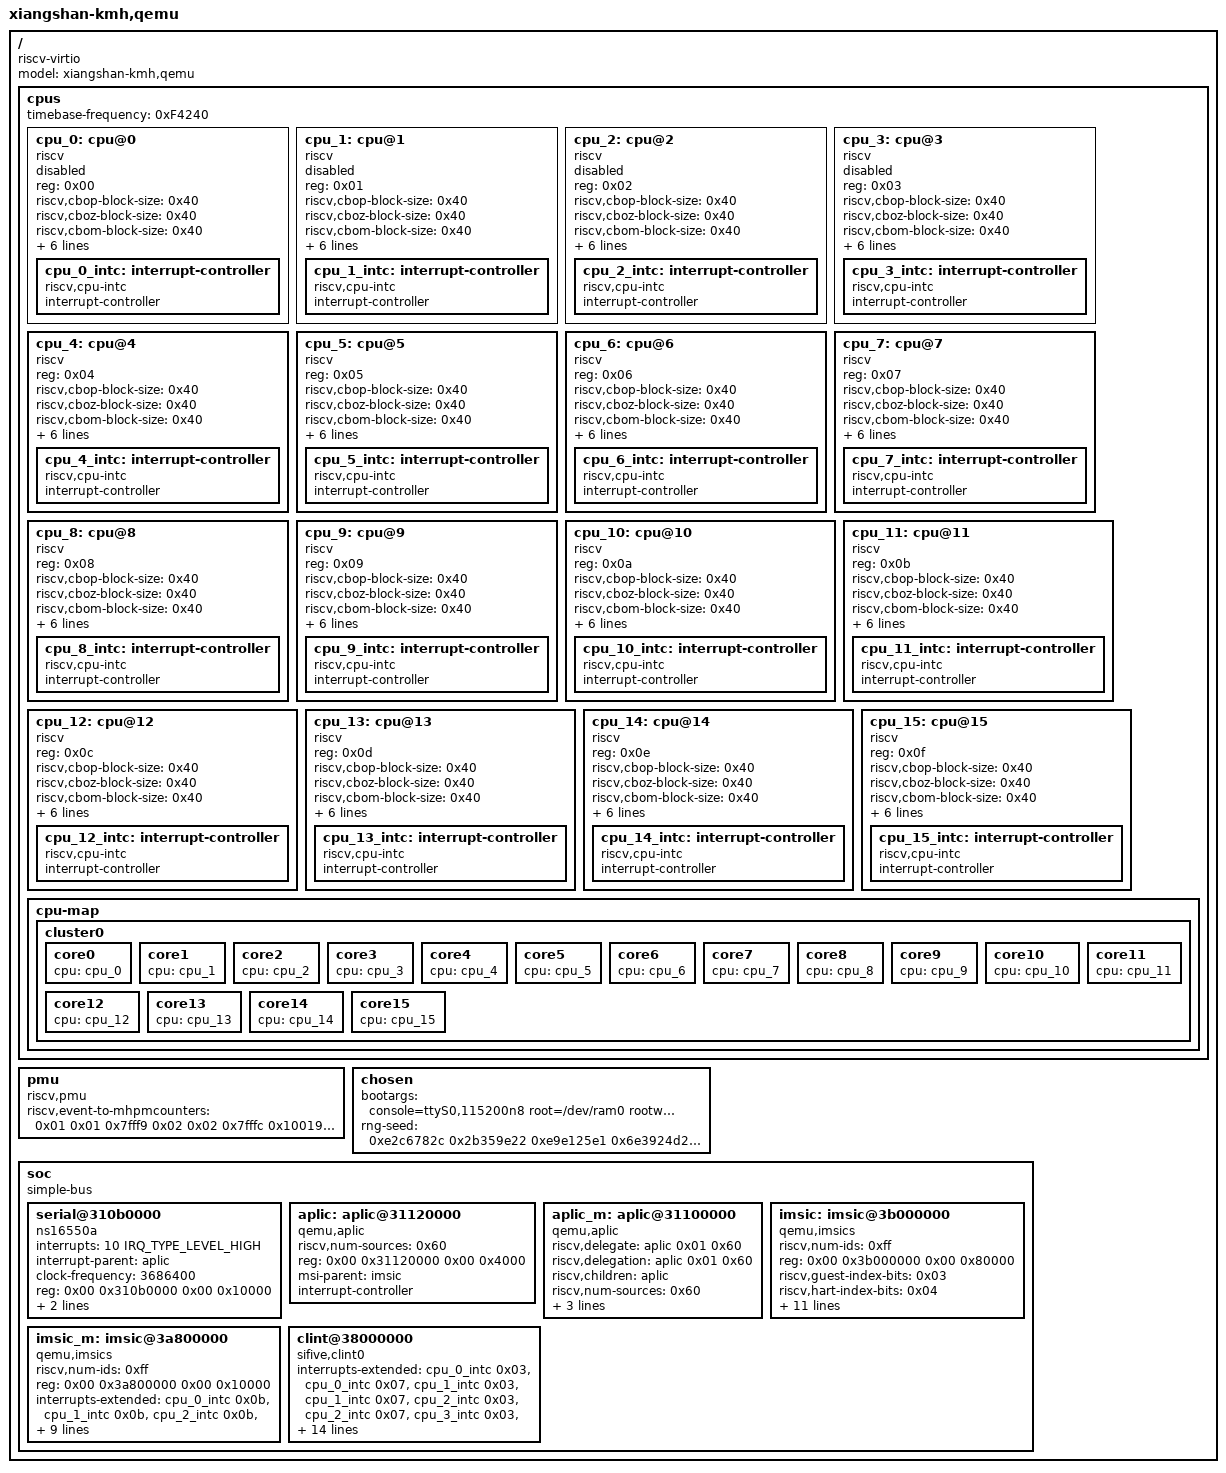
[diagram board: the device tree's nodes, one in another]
/*
 * SPDX-License-Identifier: Apache-2.0
 * Copyright (c) 2025 KapaXL (kapa.xl@outlook.com)
 *
 * QEMU RISCV xiangshan-kunminghu machine
 */

/dts-v1/;

#define IRQ_TYPE_LEVEL_HIGH	4

#include "memory.dtsi"

/ {
	#address-cells = <0x02>;
	#size-cells = <0x02>;
	compatible = "riscv-virtio";
	model = "xiangshan-kmh,qemu";

	cpus {
		#address-cells = <0x01>;
		#size-cells = <0x00>;
		timebase-frequency = <0xF4240>;

		cpu_0: cpu@0 {
			device_type = "cpu";
			reg = <0x00>;
			status = "disabled";
			compatible = "riscv";
			riscv,cbop-block-size = <0x40>;
			riscv,cboz-block-size = <0x40>;
			riscv,cbom-block-size = <0x40>;
			riscv,isa-extensions = "i\0m\0a\0f\0d\0c\0h\0zic64b\0zicbom\0zicbop\0zicboz\0ziccamoa\0ziccif\0zicclsm\0ziccrse\0zicntr\0zicsr\0zifencei\0zihintntl\0zihintpause\0zihpm\0zmmul\0za64rs\0zaamo\0zalrsc\0zawrs\0zfa\0zca\0zcd\0zba\0zbb\0zbc\0zbs\0sdtrig\0shcounterenw\0shgatpa\0shtvala\0shvsatpa\0shvstvala\0shvstvecd\0smaia\0ssaia\0ssccptr\0sscounterenw\0ssstrict\0sstc\0sstvala\0sstvecd\0ssu64xl\0svadu\0svvptc";
			riscv,isa-base = "rv64i";
			riscv,isa = "rv64imafdch_zic64b_zicbom_zicbop_zicboz_ziccamoa_ziccif_zicclsm_ziccrse_zicntr_zicsr_zifencei_zihintntl_zihintpause_zihpm_zmmul_za64rs_zaamo_zalrsc_zawrs_zfa_zca_zcd_zba_zbb_zbc_zbs_sdtrig_shcounterenw_shgatpa_shtvala_shvsatpa_shvstvala_shvstvecd_smaia_ssaia_ssccptr_sscounterenw_ssstrict_sstc_sstvala_sstvecd_ssu64xl_svadu_svvptc";
			mmu-type = "riscv,sv57";

			cpu_0_intc: interrupt-controller {
				#interrupt-cells = <0x01>;
				interrupt-controller;
				compatible = "riscv,cpu-intc";
			};
		};

		cpu_1: cpu@1 {
			device_type = "cpu";
			reg = <0x01>;
			status = "disabled";
			compatible = "riscv";
			riscv,cbop-block-size = <0x40>;
			riscv,cboz-block-size = <0x40>;
			riscv,cbom-block-size = <0x40>;
			riscv,isa-extensions = "i\0m\0a\0f\0d\0c\0h\0zic64b\0zicbom\0zicbop\0zicboz\0ziccamoa\0ziccif\0zicclsm\0ziccrse\0zicntr\0zicsr\0zifencei\0zihintntl\0zihintpause\0zihpm\0zmmul\0za64rs\0zaamo\0zalrsc\0zawrs\0zfa\0zca\0zcd\0zba\0zbb\0zbc\0zbs\0sdtrig\0shcounterenw\0shgatpa\0shtvala\0shvsatpa\0shvstvala\0shvstvecd\0smaia\0ssaia\0ssccptr\0sscounterenw\0ssstrict\0sstc\0sstvala\0sstvecd\0ssu64xl\0svadu\0svvptc";
			riscv,isa-base = "rv64i";
			riscv,isa = "rv64imafdch_zic64b_zicbom_zicbop_zicboz_ziccamoa_ziccif_zicclsm_ziccrse_zicntr_zicsr_zifencei_zihintntl_zihintpause_zihpm_zmmul_za64rs_zaamo_zalrsc_zawrs_zfa_zca_zcd_zba_zbb_zbc_zbs_sdtrig_shcounterenw_shgatpa_shtvala_shvsatpa_shvstvala_shvstvecd_smaia_ssaia_ssccptr_sscounterenw_ssstrict_sstc_sstvala_sstvecd_ssu64xl_svadu_svvptc";
			mmu-type = "riscv,sv57";

			cpu_1_intc: interrupt-controller {
				#interrupt-cells = <0x01>;
				interrupt-controller;
				compatible = "riscv,cpu-intc";
			};
		};
		cpu_2: cpu@2 {
			device_type = "cpu";
			reg = <0x02>;
			status = "disabled";
			compatible = "riscv";
			riscv,cbop-block-size = <0x40>;
			riscv,cboz-block-size = <0x40>;
			riscv,cbom-block-size = <0x40>;
			riscv,isa-extensions = "i\0m\0a\0f\0d\0c\0h\0zic64b\0zicbom\0zicbop\0zicboz\0ziccamoa\0ziccif\0zicclsm\0ziccrse\0zicntr\0zicsr\0zifencei\0zihintntl\0zihintpause\0zihpm\0zmmul\0za64rs\0zaamo\0zalrsc\0zawrs\0zfa\0zca\0zcd\0zba\0zbb\0zbc\0zbs\0sdtrig\0shcounterenw\0shgatpa\0shtvala\0shvsatpa\0shvstvala\0shvstvecd\0smaia\0ssaia\0ssccptr\0sscounterenw\0ssstrict\0sstc\0sstvala\0sstvecd\0ssu64xl\0svadu\0svvptc";
			riscv,isa-base = "rv64i";
			riscv,isa = "rv64imafdch_zic64b_zicbom_zicbop_zicboz_ziccamoa_ziccif_zicclsm_ziccrse_zicntr_zicsr_zifencei_zihintntl_zihintpause_zihpm_zmmul_za64rs_zaamo_zalrsc_zawrs_zfa_zca_zcd_zba_zbb_zbc_zbs_sdtrig_shcounterenw_shgatpa_shtvala_shvsatpa_shvstvala_shvstvecd_smaia_ssaia_ssccptr_sscounterenw_ssstrict_sstc_sstvala_sstvecd_ssu64xl_svadu_svvptc";
			mmu-type = "riscv,sv57";

			cpu_2_intc: interrupt-controller {
				#interrupt-cells = <0x01>;
				interrupt-controller;
				compatible = "riscv,cpu-intc";
			};
		};
		cpu_3: cpu@3 {
			device_type = "cpu";
			reg = <0x03>;
			status = "disabled";
			compatible = "riscv";
			riscv,cbop-block-size = <0x40>;
			riscv,cboz-block-size = <0x40>;
			riscv,cbom-block-size = <0x40>;
			riscv,isa-extensions = "i\0m\0a\0f\0d\0c\0h\0zic64b\0zicbom\0zicbop\0zicboz\0ziccamoa\0ziccif\0zicclsm\0ziccrse\0zicntr\0zicsr\0zifencei\0zihintntl\0zihintpause\0zihpm\0zmmul\0za64rs\0zaamo\0zalrsc\0zawrs\0zfa\0zca\0zcd\0zba\0zbb\0zbc\0zbs\0sdtrig\0shcounterenw\0shgatpa\0shtvala\0shvsatpa\0shvstvala\0shvstvecd\0smaia\0ssaia\0ssccptr\0sscounterenw\0ssstrict\0sstc\0sstvala\0sstvecd\0ssu64xl\0svadu\0svvptc";
			riscv,isa-base = "rv64i";
			riscv,isa = "rv64imafdch_zic64b_zicbom_zicbop_zicboz_ziccamoa_ziccif_zicclsm_ziccrse_zicntr_zicsr_zifencei_zihintntl_zihintpause_zihpm_zmmul_za64rs_zaamo_zalrsc_zawrs_zfa_zca_zcd_zba_zbb_zbc_zbs_sdtrig_shcounterenw_shgatpa_shtvala_shvsatpa_shvstvala_shvstvecd_smaia_ssaia_ssccptr_sscounterenw_ssstrict_sstc_sstvala_sstvecd_ssu64xl_svadu_svvptc";
			mmu-type = "riscv,sv57";

			cpu_3_intc: interrupt-controller {
				#interrupt-cells = <0x01>;
				interrupt-controller;
				compatible = "riscv,cpu-intc";
			};
		};
		cpu_4: cpu@4 {
			device_type = "cpu";
			reg = <0x04>;
			status = "okay";
			compatible = "riscv";
			riscv,cbop-block-size = <0x40>;
			riscv,cboz-block-size = <0x40>;
			riscv,cbom-block-size = <0x40>;
			riscv,isa-extensions = "i\0m\0a\0f\0d\0c\0h\0zic64b\0zicbom\0zicbop\0zicboz\0ziccamoa\0ziccif\0zicclsm\0ziccrse\0zicntr\0zicsr\0zifencei\0zihintntl\0zihintpause\0zihpm\0zmmul\0za64rs\0zaamo\0zalrsc\0zawrs\0zfa\0zca\0zcd\0zba\0zbb\0zbc\0zbs\0sdtrig\0shcounterenw\0shgatpa\0shtvala\0shvsatpa\0shvstvala\0shvstvecd\0smaia\0ssaia\0ssccptr\0sscounterenw\0ssstrict\0sstc\0sstvala\0sstvecd\0ssu64xl\0svadu\0svvptc";
			riscv,isa-base = "rv64i";
			riscv,isa = "rv64imafdch_zic64b_zicbom_zicbop_zicboz_ziccamoa_ziccif_zicclsm_ziccrse_zicntr_zicsr_zifencei_zihintntl_zihintpause_zihpm_zmmul_za64rs_zaamo_zalrsc_zawrs_zfa_zca_zcd_zba_zbb_zbc_zbs_sdtrig_shcounterenw_shgatpa_shtvala_shvsatpa_shvstvala_shvstvecd_smaia_ssaia_ssccptr_sscounterenw_ssstrict_sstc_sstvala_sstvecd_ssu64xl_svadu_svvptc";
			mmu-type = "riscv,sv57";

			cpu_4_intc: interrupt-controller {
				#interrupt-cells = <0x01>;
				interrupt-controller;
				compatible = "riscv,cpu-intc";
			};
		};
		cpu_5: cpu@5 {
			device_type = "cpu";
			reg = <0x05>;
			status = "okay";
			compatible = "riscv";
			riscv,cbop-block-size = <0x40>;
			riscv,cboz-block-size = <0x40>;
			riscv,cbom-block-size = <0x40>;
			riscv,isa-extensions = "i\0m\0a\0f\0d\0c\0h\0zic64b\0zicbom\0zicbop\0zicboz\0ziccamoa\0ziccif\0zicclsm\0ziccrse\0zicntr\0zicsr\0zifencei\0zihintntl\0zihintpause\0zihpm\0zmmul\0za64rs\0zaamo\0zalrsc\0zawrs\0zfa\0zca\0zcd\0zba\0zbb\0zbc\0zbs\0sdtrig\0shcounterenw\0shgatpa\0shtvala\0shvsatpa\0shvstvala\0shvstvecd\0smaia\0ssaia\0ssccptr\0sscounterenw\0ssstrict\0sstc\0sstvala\0sstvecd\0ssu64xl\0svadu\0svvptc";
			riscv,isa-base = "rv64i";
			riscv,isa = "rv64imafdch_zic64b_zicbom_zicbop_zicboz_ziccamoa_ziccif_zicclsm_ziccrse_zicntr_zicsr_zifencei_zihintntl_zihintpause_zihpm_zmmul_za64rs_zaamo_zalrsc_zawrs_zfa_zca_zcd_zba_zbb_zbc_zbs_sdtrig_shcounterenw_shgatpa_shtvala_shvsatpa_shvstvala_shvstvecd_smaia_ssaia_ssccptr_sscounterenw_ssstrict_sstc_sstvala_sstvecd_ssu64xl_svadu_svvptc";
			mmu-type = "riscv,sv57";

			cpu_5_intc: interrupt-controller {
				#interrupt-cells = <0x01>;
				interrupt-controller;
				compatible = "riscv,cpu-intc";
			};
		};
		cpu_6: cpu@6 {
			device_type = "cpu";
			reg = <0x06>;
			status = "okay";
			compatible = "riscv";
			riscv,cbop-block-size = <0x40>;
			riscv,cboz-block-size = <0x40>;
			riscv,cbom-block-size = <0x40>;
			riscv,isa-extensions = "i\0m\0a\0f\0d\0c\0h\0zic64b\0zicbom\0zicbop\0zicboz\0ziccamoa\0ziccif\0zicclsm\0ziccrse\0zicntr\0zicsr\0zifencei\0zihintntl\0zihintpause\0zihpm\0zmmul\0za64rs\0zaamo\0zalrsc\0zawrs\0zfa\0zca\0zcd\0zba\0zbb\0zbc\0zbs\0sdtrig\0shcounterenw\0shgatpa\0shtvala\0shvsatpa\0shvstvala\0shvstvecd\0smaia\0ssaia\0ssccptr\0sscounterenw\0ssstrict\0sstc\0sstvala\0sstvecd\0ssu64xl\0svadu\0svvptc";
			riscv,isa-base = "rv64i";
			riscv,isa = "rv64imafdch_zic64b_zicbom_zicbop_zicboz_ziccamoa_ziccif_zicclsm_ziccrse_zicntr_zicsr_zifencei_zihintntl_zihintpause_zihpm_zmmul_za64rs_zaamo_zalrsc_zawrs_zfa_zca_zcd_zba_zbb_zbc_zbs_sdtrig_shcounterenw_shgatpa_shtvala_shvsatpa_shvstvala_shvstvecd_smaia_ssaia_ssccptr_sscounterenw_ssstrict_sstc_sstvala_sstvecd_ssu64xl_svadu_svvptc";
			mmu-type = "riscv,sv57";

			cpu_6_intc: interrupt-controller {
				#interrupt-cells = <0x01>;
				interrupt-controller;
				compatible = "riscv,cpu-intc";
			};
		};
		cpu_7: cpu@7 {
			device_type = "cpu";
			reg = <0x07>;
			status = "okay";
			compatible = "riscv";
			riscv,cbop-block-size = <0x40>;
			riscv,cboz-block-size = <0x40>;
			riscv,cbom-block-size = <0x40>;
			riscv,isa-extensions = "i\0m\0a\0f\0d\0c\0h\0zic64b\0zicbom\0zicbop\0zicboz\0ziccamoa\0ziccif\0zicclsm\0ziccrse\0zicntr\0zicsr\0zifencei\0zihintntl\0zihintpause\0zihpm\0zmmul\0za64rs\0zaamo\0zalrsc\0zawrs\0zfa\0zca\0zcd\0zba\0zbb\0zbc\0zbs\0sdtrig\0shcounterenw\0shgatpa\0shtvala\0shvsatpa\0shvstvala\0shvstvecd\0smaia\0ssaia\0ssccptr\0sscounterenw\0ssstrict\0sstc\0sstvala\0sstvecd\0ssu64xl\0svadu\0svvptc";
			riscv,isa-base = "rv64i";
			riscv,isa = "rv64imafdch_zic64b_zicbom_zicbop_zicboz_ziccamoa_ziccif_zicclsm_ziccrse_zicntr_zicsr_zifencei_zihintntl_zihintpause_zihpm_zmmul_za64rs_zaamo_zalrsc_zawrs_zfa_zca_zcd_zba_zbb_zbc_zbs_sdtrig_shcounterenw_shgatpa_shtvala_shvsatpa_shvstvala_shvstvecd_smaia_ssaia_ssccptr_sscounterenw_ssstrict_sstc_sstvala_sstvecd_ssu64xl_svadu_svvptc";
			mmu-type = "riscv,sv57";

			cpu_7_intc: interrupt-controller {
				#interrupt-cells = <0x01>;
				interrupt-controller;
				compatible = "riscv,cpu-intc";
			};
		};
		cpu_8: cpu@8 {
			device_type = "cpu";
			reg = <0x08>;
			status = "okay";
			compatible = "riscv";
			riscv,cbop-block-size = <0x40>;
			riscv,cboz-block-size = <0x40>;
			riscv,cbom-block-size = <0x40>;
			riscv,isa-extensions = "i\0m\0a\0f\0d\0c\0h\0zic64b\0zicbom\0zicbop\0zicboz\0ziccamoa\0ziccif\0zicclsm\0ziccrse\0zicntr\0zicsr\0zifencei\0zihintntl\0zihintpause\0zihpm\0zmmul\0za64rs\0zaamo\0zalrsc\0zawrs\0zfa\0zca\0zcd\0zba\0zbb\0zbc\0zbs\0sdtrig\0shcounterenw\0shgatpa\0shtvala\0shvsatpa\0shvstvala\0shvstvecd\0smaia\0ssaia\0ssccptr\0sscounterenw\0ssstrict\0sstc\0sstvala\0sstvecd\0ssu64xl\0svadu\0svvptc";
			riscv,isa-base = "rv64i";
			riscv,isa = "rv64imafdch_zic64b_zicbom_zicbop_zicboz_ziccamoa_ziccif_zicclsm_ziccrse_zicntr_zicsr_zifencei_zihintntl_zihintpause_zihpm_zmmul_za64rs_zaamo_zalrsc_zawrs_zfa_zca_zcd_zba_zbb_zbc_zbs_sdtrig_shcounterenw_shgatpa_shtvala_shvsatpa_shvstvala_shvstvecd_smaia_ssaia_ssccptr_sscounterenw_ssstrict_sstc_sstvala_sstvecd_ssu64xl_svadu_svvptc";
			mmu-type = "riscv,sv57";

			cpu_8_intc: interrupt-controller {
				#interrupt-cells = <0x01>;
				interrupt-controller;
				compatible = "riscv,cpu-intc";
			};
		};
		cpu_9: cpu@9 {
			device_type = "cpu";
			reg = <0x09>;
			status = "okay";
			compatible = "riscv";
			riscv,cbop-block-size = <0x40>;
			riscv,cboz-block-size = <0x40>;
			riscv,cbom-block-size = <0x40>;
			riscv,isa-extensions = "i\0m\0a\0f\0d\0c\0h\0zic64b\0zicbom\0zicbop\0zicboz\0ziccamoa\0ziccif\0zicclsm\0ziccrse\0zicntr\0zicsr\0zifencei\0zihintntl\0zihintpause\0zihpm\0zmmul\0za64rs\0zaamo\0zalrsc\0zawrs\0zfa\0zca\0zcd\0zba\0zbb\0zbc\0zbs\0sdtrig\0shcounterenw\0shgatpa\0shtvala\0shvsatpa\0shvstvala\0shvstvecd\0smaia\0ssaia\0ssccptr\0sscounterenw\0ssstrict\0sstc\0sstvala\0sstvecd\0ssu64xl\0svadu\0svvptc";
			riscv,isa-base = "rv64i";
			riscv,isa = "rv64imafdch_zic64b_zicbom_zicbop_zicboz_ziccamoa_ziccif_zicclsm_ziccrse_zicntr_zicsr_zifencei_zihintntl_zihintpause_zihpm_zmmul_za64rs_zaamo_zalrsc_zawrs_zfa_zca_zcd_zba_zbb_zbc_zbs_sdtrig_shcounterenw_shgatpa_shtvala_shvsatpa_shvstvala_shvstvecd_smaia_ssaia_ssccptr_sscounterenw_ssstrict_sstc_sstvala_sstvecd_ssu64xl_svadu_svvptc";
			mmu-type = "riscv,sv57";

			cpu_9_intc: interrupt-controller {
				#interrupt-cells = <0x01>;
				interrupt-controller;
				compatible = "riscv,cpu-intc";
			};
		};
		cpu_10: cpu@10 {
			device_type = "cpu";
			reg = <0x0a>;
			status = "okay";
			compatible = "riscv";
			riscv,cbop-block-size = <0x40>;
			riscv,cboz-block-size = <0x40>;
			riscv,cbom-block-size = <0x40>;
			riscv,isa-extensions = "i\0m\0a\0f\0d\0c\0h\0zic64b\0zicbom\0zicbop\0zicboz\0ziccamoa\0ziccif\0zicclsm\0ziccrse\0zicntr\0zicsr\0zifencei\0zihintntl\0zihintpause\0zihpm\0zmmul\0za64rs\0zaamo\0zalrsc\0zawrs\0zfa\0zca\0zcd\0zba\0zbb\0zbc\0zbs\0sdtrig\0shcounterenw\0shgatpa\0shtvala\0shvsatpa\0shvstvala\0shvstvecd\0smaia\0ssaia\0ssccptr\0sscounterenw\0ssstrict\0sstc\0sstvala\0sstvecd\0ssu64xl\0svadu\0svvptc";
			riscv,isa-base = "rv64i";
			riscv,isa = "rv64imafdch_zic64b_zicbom_zicbop_zicboz_ziccamoa_ziccif_zicclsm_ziccrse_zicntr_zicsr_zifencei_zihintntl_zihintpause_zihpm_zmmul_za64rs_zaamo_zalrsc_zawrs_zfa_zca_zcd_zba_zbb_zbc_zbs_sdtrig_shcounterenw_shgatpa_shtvala_shvsatpa_shvstvala_shvstvecd_smaia_ssaia_ssccptr_sscounterenw_ssstrict_sstc_sstvala_sstvecd_ssu64xl_svadu_svvptc";
			mmu-type = "riscv,sv57";

			cpu_10_intc: interrupt-controller {
				#interrupt-cells = <0x01>;
				interrupt-controller;
				compatible = "riscv,cpu-intc";
			};
		};
		cpu_11: cpu@11 {
			device_type = "cpu";
			reg = <0x0b>;
			status = "okay";
			compatible = "riscv";
			riscv,cbop-block-size = <0x40>;
			riscv,cboz-block-size = <0x40>;
			riscv,cbom-block-size = <0x40>;
			riscv,isa-extensions = "i\0m\0a\0f\0d\0c\0h\0zic64b\0zicbom\0zicbop\0zicboz\0ziccamoa\0ziccif\0zicclsm\0ziccrse\0zicntr\0zicsr\0zifencei\0zihintntl\0zihintpause\0zihpm\0zmmul\0za64rs\0zaamo\0zalrsc\0zawrs\0zfa\0zca\0zcd\0zba\0zbb\0zbc\0zbs\0sdtrig\0shcounterenw\0shgatpa\0shtvala\0shvsatpa\0shvstvala\0shvstvecd\0smaia\0ssaia\0ssccptr\0sscounterenw\0ssstrict\0sstc\0sstvala\0sstvecd\0ssu64xl\0svadu\0svvptc";
			riscv,isa-base = "rv64i";
			riscv,isa = "rv64imafdch_zic64b_zicbom_zicbop_zicboz_ziccamoa_ziccif_zicclsm_ziccrse_zicntr_zicsr_zifencei_zihintntl_zihintpause_zihpm_zmmul_za64rs_zaamo_zalrsc_zawrs_zfa_zca_zcd_zba_zbb_zbc_zbs_sdtrig_shcounterenw_shgatpa_shtvala_shvsatpa_shvstvala_shvstvecd_smaia_ssaia_ssccptr_sscounterenw_ssstrict_sstc_sstvala_sstvecd_ssu64xl_svadu_svvptc";
			mmu-type = "riscv,sv57";

			cpu_11_intc: interrupt-controller {
				#interrupt-cells = <0x01>;
				interrupt-controller;
				compatible = "riscv,cpu-intc";
			};
		};
		cpu_12: cpu@12 {
			device_type = "cpu";
			reg = <0x0c>;
			status = "okay";
			compatible = "riscv";
			riscv,cbop-block-size = <0x40>;
			riscv,cboz-block-size = <0x40>;
			riscv,cbom-block-size = <0x40>;
			riscv,isa-extensions = "i\0m\0a\0f\0d\0c\0h\0zic64b\0zicbom\0zicbop\0zicboz\0ziccamoa\0ziccif\0zicclsm\0ziccrse\0zicntr\0zicsr\0zifencei\0zihintntl\0zihintpause\0zihpm\0zmmul\0za64rs\0zaamo\0zalrsc\0zawrs\0zfa\0zca\0zcd\0zba\0zbb\0zbc\0zbs\0sdtrig\0shcounterenw\0shgatpa\0shtvala\0shvsatpa\0shvstvala\0shvstvecd\0smaia\0ssaia\0ssccptr\0sscounterenw\0ssstrict\0sstc\0sstvala\0sstvecd\0ssu64xl\0svadu\0svvptc";
			riscv,isa-base = "rv64i";
			riscv,isa = "rv64imafdch_zic64b_zicbom_zicbop_zicboz_ziccamoa_ziccif_zicclsm_ziccrse_zicntr_zicsr_zifencei_zihintntl_zihintpause_zihpm_zmmul_za64rs_zaamo_zalrsc_zawrs_zfa_zca_zcd_zba_zbb_zbc_zbs_sdtrig_shcounterenw_shgatpa_shtvala_shvsatpa_shvstvala_shvstvecd_smaia_ssaia_ssccptr_sscounterenw_ssstrict_sstc_sstvala_sstvecd_ssu64xl_svadu_svvptc";
			mmu-type = "riscv,sv57";

			cpu_12_intc: interrupt-controller {
				#interrupt-cells = <0x01>;
				interrupt-controller;
				compatible = "riscv,cpu-intc";
			};
		};
		cpu_13: cpu@13 {
			device_type = "cpu";
			reg = <0x0d>;
			status = "okay";
			compatible = "riscv";
			riscv,cbop-block-size = <0x40>;
			riscv,cboz-block-size = <0x40>;
			riscv,cbom-block-size = <0x40>;
			riscv,isa-extensions = "i\0m\0a\0f\0d\0c\0h\0zic64b\0zicbom\0zicbop\0zicboz\0ziccamoa\0ziccif\0zicclsm\0ziccrse\0zicntr\0zicsr\0zifencei\0zihintntl\0zihintpause\0zihpm\0zmmul\0za64rs\0zaamo\0zalrsc\0zawrs\0zfa\0zca\0zcd\0zba\0zbb\0zbc\0zbs\0sdtrig\0shcounterenw\0shgatpa\0shtvala\0shvsatpa\0shvstvala\0shvstvecd\0smaia\0ssaia\0ssccptr\0sscounterenw\0ssstrict\0sstc\0sstvala\0sstvecd\0ssu64xl\0svadu\0svvptc";
			riscv,isa-base = "rv64i";
			riscv,isa = "rv64imafdch_zic64b_zicbom_zicbop_zicboz_ziccamoa_ziccif_zicclsm_ziccrse_zicntr_zicsr_zifencei_zihintntl_zihintpause_zihpm_zmmul_za64rs_zaamo_zalrsc_zawrs_zfa_zca_zcd_zba_zbb_zbc_zbs_sdtrig_shcounterenw_shgatpa_shtvala_shvsatpa_shvstvala_shvstvecd_smaia_ssaia_ssccptr_sscounterenw_ssstrict_sstc_sstvala_sstvecd_ssu64xl_svadu_svvptc";
			mmu-type = "riscv,sv57";

			cpu_13_intc: interrupt-controller {
				#interrupt-cells = <0x01>;
				interrupt-controller;
				compatible = "riscv,cpu-intc";
			};
		};
		cpu_14: cpu@14 {
			device_type = "cpu";
			reg = <0x0e>;
			status = "okay";
			compatible = "riscv";
			riscv,cbop-block-size = <0x40>;
			riscv,cboz-block-size = <0x40>;
			riscv,cbom-block-size = <0x40>;
			riscv,isa-extensions = "i\0m\0a\0f\0d\0c\0h\0zic64b\0zicbom\0zicbop\0zicboz\0ziccamoa\0ziccif\0zicclsm\0ziccrse\0zicntr\0zicsr\0zifencei\0zihintntl\0zihintpause\0zihpm\0zmmul\0za64rs\0zaamo\0zalrsc\0zawrs\0zfa\0zca\0zcd\0zba\0zbb\0zbc\0zbs\0sdtrig\0shcounterenw\0shgatpa\0shtvala\0shvsatpa\0shvstvala\0shvstvecd\0smaia\0ssaia\0ssccptr\0sscounterenw\0ssstrict\0sstc\0sstvala\0sstvecd\0ssu64xl\0svadu\0svvptc";
			riscv,isa-base = "rv64i";
			riscv,isa = "rv64imafdch_zic64b_zicbom_zicbop_zicboz_ziccamoa_ziccif_zicclsm_ziccrse_zicntr_zicsr_zifencei_zihintntl_zihintpause_zihpm_zmmul_za64rs_zaamo_zalrsc_zawrs_zfa_zca_zcd_zba_zbb_zbc_zbs_sdtrig_shcounterenw_shgatpa_shtvala_shvsatpa_shvstvala_shvstvecd_smaia_ssaia_ssccptr_sscounterenw_ssstrict_sstc_sstvala_sstvecd_ssu64xl_svadu_svvptc";
			mmu-type = "riscv,sv57";

			cpu_14_intc: interrupt-controller {
				#interrupt-cells = <0x01>;
				interrupt-controller;
				compatible = "riscv,cpu-intc";
			};
		};
		cpu_15: cpu@15 {
			device_type = "cpu";
			reg = <0x0f>;
			status = "okay";
			compatible = "riscv";
			riscv,cbop-block-size = <0x40>;
			riscv,cboz-block-size = <0x40>;
			riscv,cbom-block-size = <0x40>;
			riscv,isa-extensions = "i\0m\0a\0f\0d\0c\0h\0zic64b\0zicbom\0zicbop\0zicboz\0ziccamoa\0ziccif\0zicclsm\0ziccrse\0zicntr\0zicsr\0zifencei\0zihintntl\0zihintpause\0zihpm\0zmmul\0za64rs\0zaamo\0zalrsc\0zawrs\0zfa\0zca\0zcd\0zba\0zbb\0zbc\0zbs\0sdtrig\0shcounterenw\0shgatpa\0shtvala\0shvsatpa\0shvstvala\0shvstvecd\0smaia\0ssaia\0ssccptr\0sscounterenw\0ssstrict\0sstc\0sstvala\0sstvecd\0ssu64xl\0svadu\0svvptc";
			riscv,isa-base = "rv64i";
			riscv,isa = "rv64imafdch_zic64b_zicbom_zicbop_zicboz_ziccamoa_ziccif_zicclsm_ziccrse_zicntr_zicsr_zifencei_zihintntl_zihintpause_zihpm_zmmul_za64rs_zaamo_zalrsc_zawrs_zfa_zca_zcd_zba_zbb_zbc_zbs_sdtrig_shcounterenw_shgatpa_shtvala_shvsatpa_shvstvala_shvstvecd_smaia_ssaia_ssccptr_sscounterenw_ssstrict_sstc_sstvala_sstvecd_ssu64xl_svadu_svvptc";
			mmu-type = "riscv,sv57";

			cpu_15_intc: interrupt-controller {
				#interrupt-cells = <0x01>;
				interrupt-controller;
				compatible = "riscv,cpu-intc";
			};
		};

		cpu-map {
			cluster0 {
				core0 {
					cpu = <&cpu_0>;
				};

				core1 {
					cpu = <&cpu_1>;
				};

				core2 {
					cpu = <&cpu_2>;
				};

				core3 {
					cpu = <&cpu_3>;
				};

				core4 {
					cpu = <&cpu_4>;
				};

				core5 {
					cpu = <&cpu_5>;
				};

				core6 {
					cpu = <&cpu_6>;
				};

				core7 {
					cpu = <&cpu_7>;
				};

				core8 {
					cpu = <&cpu_8>;
				};

				core9 {
					cpu = <&cpu_9>;
				};

				core10 {
					cpu = <&cpu_10>;
				};

				core11 {
					cpu = <&cpu_11>;
				};

				core12 {
					cpu = <&cpu_12>;
				};

				core13 {
					cpu = <&cpu_13>;
				};

				core14 {
					cpu = <&cpu_14>;
				};

				core15 {
					cpu = <&cpu_15>;
				};
			};
		};
	};

	pmu {
		riscv,event-to-mhpmcounters = <0x01 0x01 0x7fff9 0x02 0x02 0x7fffc 0x10019 0x10019 0x7fff8 0x1001b 0x1001b 0x7fff8 0x10021 0x10021 0x7fff8>;
		compatible = "riscv,pmu";
	};

	chosen {
		bootargs = "console=ttyS0,115200n8 root=/dev/ram0 rootwait earlycon=sbi";
		rng-seed = <0xe2c6782c 0x2b359e22 0xe9e125e1 0x6e3924d2 0xe0a21da0 0x62f5a8a0 0x558f7d19 0x67b384c9>;
	};

	soc {
		#address-cells = <0x02>;
		#size-cells = <0x02>;
		compatible = "simple-bus";
		ranges;

		serial@310b0000 {
			compatible = "ns16550a";
			interrupts = <10 IRQ_TYPE_LEVEL_HIGH>;
			interrupt-parent = <&aplic>;
			clock-frequency = <3686400>;
			reg = <0x00 0x310b0000 0x00 0x10000>;
			reg-shift = <2>;
			reg-io-width = <1>;
		};

		aplic: aplic@31120000 {
			riscv,num-sources = <0x60>;
			reg = <0x00 0x31120000 0x00 0x4000>;
			msi-parent = <&imsic>;
			interrupt-controller;
			#interrupt-cells = <0x02>;
			#address-cells = <0x00>;
			compatible = "qemu,aplic\0riscv,aplic";
		};

		aplic_m: aplic@31100000 {
			riscv,delegate = <&aplic 0x01 0x60>;
			riscv,delegation = <&aplic 0x01 0x60>;
			riscv,children = <&aplic>;
			riscv,num-sources = <0x60>;
			reg = <0x00 0x31100000 0x00 0x4000>;
			msi-parent = <&imsic_m>;
			interrupt-controller;
			#interrupt-cells = <0x01>;
			#address-cells = <0x00>;
			compatible = "qemu,aplic\0riscv,aplic";
		};

		imsic: imsic@3b000000 {
			riscv,num-ids = <0xff>;
			reg = <0x00 0x3b000000 0x00 0x80000>;
			riscv,guest-index-bits = <0x03>;
			riscv,hart-index-bits = <0x04>;
			interrupts-extended = <
					&cpu_0_intc 0x09 &cpu_1_intc 0x09
					&cpu_2_intc 0x09 &cpu_3_intc 0x09
					&cpu_4_intc 0x09 &cpu_5_intc 0x09
					&cpu_6_intc 0x09 &cpu_7_intc 0x09
					&cpu_8_intc 0x09 &cpu_9_intc 0x09
					&cpu_10_intc 0x09 &cpu_11_intc 0x09
					&cpu_12_intc 0x09 &cpu_13_intc 0x09
					&cpu_14_intc 0x09 &cpu_15_intc 0x09>;
			msi-controller;
			interrupt-controller;
			#interrupt-cells = <0x00>;
			compatible = "qemu,imsics\0riscv,imsics";
		};

		imsic_m: imsic@3a800000 {
			riscv,num-ids = <0xff>;
			reg = <0x00 0x3a800000 0x00 0x10000>;
			interrupts-extended = <
					&cpu_0_intc 0x0b &cpu_1_intc 0x0b
					&cpu_2_intc 0x0b &cpu_3_intc 0x0b
					&cpu_4_intc 0x0b &cpu_5_intc 0x0b
					&cpu_6_intc 0x0b &cpu_7_intc 0x0b
					&cpu_8_intc 0x0b &cpu_9_intc 0x0b
					&cpu_10_intc 0x0b &cpu_11_intc 0x0b
					&cpu_12_intc 0x0b &cpu_13_intc 0x0b
					&cpu_14_intc 0x0b &cpu_15_intc 0x0b>;
			msi-controller;
			interrupt-controller;
			#interrupt-cells = <0x00>;
			compatible = "qemu,imsics\0riscv,imsics";
		};

		clint@38000000 {
			interrupts-extended = <
					&cpu_0_intc 0x03 &cpu_0_intc 0x07 &cpu_1_intc 0x03 &cpu_1_intc 0x07
					&cpu_2_intc 0x03 &cpu_2_intc 0x07 &cpu_3_intc 0x03 &cpu_3_intc 0x07
					&cpu_4_intc 0x03 &cpu_4_intc 0x07 &cpu_5_intc 0x03 &cpu_5_intc 0x07
					&cpu_6_intc 0x03 &cpu_6_intc 0x07 &cpu_7_intc 0x03 &cpu_7_intc 0x07
					&cpu_8_intc 0x03 &cpu_8_intc 0x07 &cpu_9_intc 0x03 &cpu_9_intc 0x07
					&cpu_10_intc 0x03 &cpu_10_intc 0x07 &cpu_11_intc 0x03 &cpu_11_intc 0x07
					&cpu_12_intc 0x03 &cpu_12_intc 0x07 &cpu_13_intc 0x03 &cpu_13_intc 0x07
					&cpu_14_intc 0x03 &cpu_14_intc 0x07 &cpu_15_intc 0x03 &cpu_15_intc 0x07>;
			reg = <0x00 0x38000000 0x00 0x10000>;
			compatible = "sifive,clint0\0riscv,clint0";
		};
	};
};
